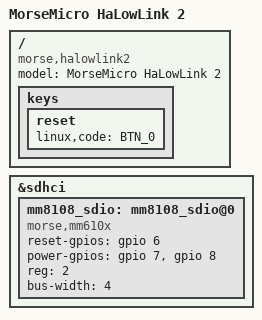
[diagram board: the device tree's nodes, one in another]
// SPDX-License-Identifier: GPL-2.0-or-later OR MIT

#include "mt7621_morse_halowlink.dtsi"

/ {
	compatible = "morse,halowlink2", "mediatek,mt7621-soc";
	model = "MorseMicro HaLowLink 2";

	/* Use button for modeswitch instead of reset */
	keys {
		reset {
			linux,code = <BTN_0>;
		};
	};
};

&sdhci {
	mm8108_sdio: mm8108_sdio@0 {
		compatible = "morse,mm610x", "morsemicro,mm81x";
		reset-gpios = <&gpio 6 0>;
		power-gpios = <&gpio 7 0>,
		              <&gpio 8 0>;
		status = "okay";
		reg = <2>;
		bus-width = <4>;
	};
};
